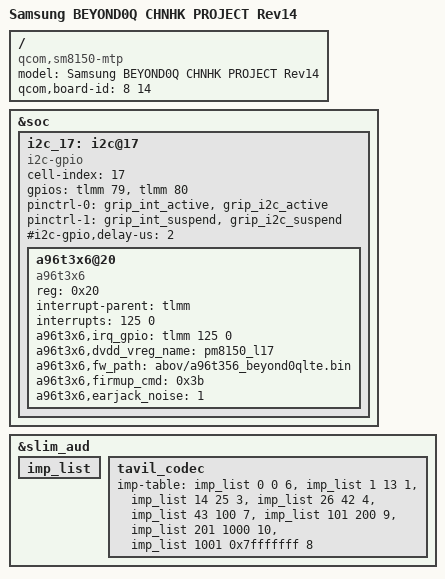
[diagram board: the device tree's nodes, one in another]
/* Copyright (c) 2016-2017, The Linux Foundation. All rights reserved.
 *
 * This program is free software; you can redistribute it and/or modify
 * it under the terms of the GNU General Public License version 2 and
 * only version 2 as published by the Free Software Foundation.
 *
 * This program is distributed in the hope that it will be useful,
 * but WITHOUT ANY WARRANTY; without even the implied warranty of
 * MERCHANTABILITY or FITNESS FOR A PARTICULAR PURPOSE.  See the
 * GNU General Public License for more details.
 */

/dts-v1/;
/plugin/;

#include <dt-bindings/clock/qcom,gcc-sm8150.h>
#include <dt-bindings/clock/qcom,camcc-sm8150.h>
#include <dt-bindings/clock/qcom,rpmh.h>
#include <dt-bindings/interrupt-controller/arm-gic.h>

#include "../qcom/sm8150-mtp.dtsi"
#include "sm8150-sec-common.dtsi"
#include "sm8150-sec-beyondqlte-pm-common.dtsi"
#include "sm8150-sec-beyond0qlte-input-common.dtsi"
#include "sm8150-sec-beyond0qlte-r14.dtsi"
#include "sm8150-sec-beyond0qlte-pinctrl-r14.dtsi"
#include "sm8150-sec-beyond0qlte-display-r00.dtsi"
#include "sm8150-sec-beyond2qlte-displayport-r14.dtsi"
#include "battery-data-beyond0qlte-common.dtsi"
#include "sm8150-max77705.dtsi"
#include "sm8150-max77705-motor.dtsi"
#include "sm8150-sec-beyond2qlte-sensor-common.dtsi"
#include "sm8150-sec-beyond0qlte-fingerprint-sensor-r04.dtsi"
#include "sm8150-sec-beyond2qlte-nfc-r04.dtsi"
#include "sm8150-camera-sensor-beyond0qlte-r08.dtsi"
#include "sm8150-sec-beyondq-mst-r04.dtsi"

/ {
	model = "Samsung BEYOND0Q CHNHK PROJECT Rev14";
	compatible = "qcom,sm8150-mtp", "qcom,sm8150", "qcom,mtp";
	qcom,board-id = <8 14>;
};

/delete-node/ &i2c_17;

&soc {
	i2c_17: i2c@17 { /* SW I2C */
		status = "ok";

		cell-index = <17>;
		compatible = "i2c-gpio";
		gpios = <&tlmm 79 0 /* sda */
			 &tlmm 80 0 /* scl */
		>;
		pinctrl-names = "default", "sleep";
		pinctrl-0 = <&grip_int_active &grip_i2c_active>;
		pinctrl-1 = <&grip_int_suspend &grip_i2c_suspend>;

		#i2c-gpio,delay-us = <2>;
		#address-cells = <1>;
		#size-cells = <0>;
		a96t3x6@20 {
			compatible = "a96t3x6";
			reg = <0x20>;

			interrupt-parent = <&tlmm>;
			interrupts = <125 0>;

			a96t3x6,irq_gpio = <&tlmm 125 0>;
			a96t3x6,dvdd_vreg_name = "pm8150_l17";
			a96t3x6,fw_path = "abov/a96t356_beyond0qlte.bin";
			a96t3x6,firmup_cmd = <0x3b>;
			a96t3x6,earjack_noise = <1>;
		};
	};
};

&slim_aud {
	imp_list: imp_list {
		#list-imp-cells = <3>;
	};

	tavil_codec {
		imp-table = <&imp_list 0 0 6>,
				 <&imp_list 1 13 1>,
				 <&imp_list 14 25 3>,
				 <&imp_list 26 42 4>,
				 <&imp_list 43 100 7>,
				 <&imp_list 101 200 9>,
				 <&imp_list 201 1000 10>,
				 <&imp_list 1001 0x7fffffff 8>;
	};
};
